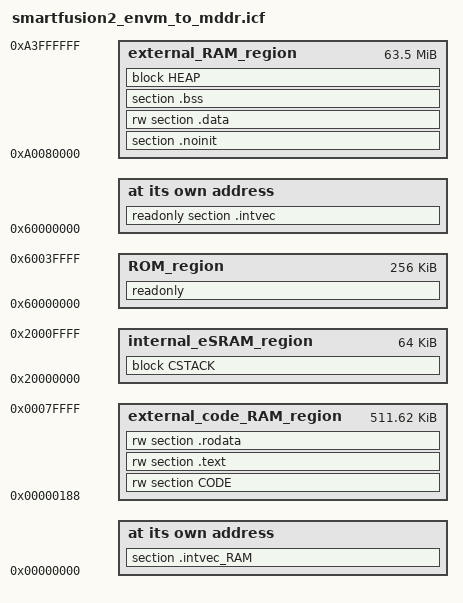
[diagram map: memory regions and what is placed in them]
/******************************************************************************/
/*  (c) Copyright 2015 Microsemi SoC Products Group. All rights reserved.     */
/*  SmartFusion2 linker configuration file for relocating code from eNVM to   */
/*  external RAM.                                                             */
/*                                                                            */
/*  SVN $Revision: 7732 $                                                     */
/*  SVN $Date: 2015-09-02 15:26:06 +0100 (Wed, 02 Sep 2015) $                 */
/*                                                                            */
/*  Please Note!!!!!!                                                         */
/*  The following pre-processor define must be added to the project when      */
/*  using this script- envm to mddr. This is to ensure interrupt vectors and  */ 
/*  associated code is relocated to external memory                           */
/*  MSCC_RELOCATE_CODE_TO_EXT_RAM                                             */ 
/******************************************************************************/
/* 
 * Some current (April 2015) dev kit memory map possibilities are
 * --Type-------Device-----------address start---address end----size---Dbus--RAM IC-------SF2--Comment---------------
 * --eNVM-------M2S010-----------0x60000000------0x6007FFFF-----256KB---------------------010------------------------
 * --eNVM-------M2S090-----------0x60000000------0x6007FFFF-----512KB---------------------090------------------------
 * --eSRAM------M2Sxxx-----------0x20000000------0x2000FFFF-----64KB----------------------xxx--All have same amount--
 * --eSRAM------M2Sxxx-----------0x20000000------0x20013FFF-----80KB----------------------xxx--If ECC/SECDED not used
 * --Fabric-----M2S010-----------0x30000000------0x6007FFFF-----400Kb---------------------010--note-K bits-----------
 * --Fabric-----M2S090-----------0x30000000------0x6007FFFF-----2074Kb--------------------090--note-K bits-----------
 * --LPDDR------STARTER-KIT------0xA0000000------0xA3FFFFFF-----64MB---16--MT46H32M16-----050------------------------
 * --LPDDR------484-STARTER-KIT--0xA0000000------0xA3FFFFFF-----64MB---16--MT46H32M16-----010------------------------
 * --LPDDR------SEC-EVAL-KIT-----0xA0000000------0xA3FFFFFF-----64MB---16--MT46H32M16LF---090--Security eval kit-----
 * --DDR3-------ADevKit----------0xA0000000------0xBFFFFFFF-----1GB----32--MT41K256M8DA---150------------------------
 * --Some older physical memory map possibilities are
 * --Type-------location---------address start---address end----size---Dbus---RAM IC------SF2--Comment--------------
 * --LPDDR------EVAL KIT---------0xA0000000------0xA3FFFFFF-----64MB-=-16--MT46H32M16LF---025--Eval Kit--------------
 * --DDR3-------DevKit-----------0xA0000000------0xAFFFFFFF-----512MB--16--MT41K256M8DA---050------------------------
 */
/*###ICF### Section handled by ICF editor, don't touch! ****/
/*-Editor annotation file-*/
/* IcfEditorFile="$TOOLKIT_DIR$\config\ide\IcfEditor\cortex_v1_0.xml" */
/*-Specials-*/
define symbol __ICFEDIT_intvec_start__ = 0x60000000;
/*-Memory Regions-*/
define symbol __ICFEDIT_region_ROM_start__ = 0x60000000;
define symbol __ICFEDIT_region_ROM_end__   = 0x6003FFFF;
define symbol __ICFEDIT_region_RAM_start__ = 0xA0080000;
define symbol __ICFEDIT_region_RAM_end__   = 0xA3FFFFFF;
/*-Sizes-*/
define symbol __ICFEDIT_size_cstack__ = 0x1000;
define symbol __ICFEDIT_size_heap__   = 0x8000;
/**** End of ICF editor section. ###ICF###*/

define symbol region_internal_eSRAM_start = 0x20000000;
define symbol region_internal_eSRAM_end   = 0x2000FFFF;

define symbol region_external_code_RAM_start = 0x00000188;
define symbol region_external_code_RAM_end = 0x0007FFFF;

define symbol RAM_vectors_start = 0x00000000;

define memory mem with size = 4G;
define region ROM_region   = mem:[from __ICFEDIT_region_ROM_start__   to __ICFEDIT_region_ROM_end__];
define region internal_eSRAM_region   = mem:[from region_internal_eSRAM_start   to region_internal_eSRAM_end];

define region external_RAM_region   = mem:[from __ICFEDIT_region_RAM_start__   to __ICFEDIT_region_RAM_end__];

define region external_code_RAM_region = mem:[from region_external_code_RAM_start   to region_external_code_RAM_end];

define block CSTACK    with alignment = 8, size = __ICFEDIT_size_cstack__   { };
define block HEAP      with alignment = 8, size = __ICFEDIT_size_heap__     { };

/*  Please Note!!!!!!                                                         */
/*  The following pre-processor define must be added to the project when      */
/*  using this script- envm to mddr. This is to ensure interrupt vectors and  */ 
/*  associated code is relocated to external memory                           */
/*  MSCC_RELOCATE_CODE_TO_EXT_RAM                                             */
initialize by copy with packing = none { readonly, readwrite };
do not initialize  { section .noinit };

place at address mem:__ICFEDIT_intvec_start__ { readonly section .intvec };
place at address mem:RAM_vectors_start { section .intvec_RAM };

place in ROM_region   { readonly };
place in external_code_RAM_region { rw section CODE, rw section .text, rw section .rodata };
place in internal_eSRAM_region   { block CSTACK };
place in external_RAM_region   { section .noinit, rw section .data, section .bss, block HEAP };

/* Note taken from IAR system Technical Note 11578 -- Linker protection of start up code        */ 
/* The linker protects sections that are referenced from the startup code from being affected   */ 
/* by an 'initialize by copy' directive.                                                        */ 
/* This includes                                                                                */ 
/*      * __low_level_init and all functions called and/or defined in the same                  */ 
/*       compilation unit (.c file)                                                             */ 
/*      * global (statically linked) C/C++ symbols                                              */ 
/* So the linker ensures that only code that runs after copy initialization has been finished   */ 
/* will be copied to RAM. For this reason it is safe to add readonly in the                     */ 
/* initialize by copy { readonly, readwrite }; command.                                         */ 
/* The linker log (option --log sections) is extended in EWARM 6.10 with information of symbols */ 
/* marked as 'needed for init'.                                                                 */ 
/* Look at the end of the generated log file if you want to see a list of the items not copied  */
/* e.g.:                                                                                        */
/* The following sections would have been initialized by copy but were                          */
/*   excluded because they were marked as possibly 'needed for init':                           */
/*    .intvec (vector_table.o #8)                                                               */
/*    .rodata (sys_config.o #8)                                                                 */
/*    .rodata (sys_config.o #9)                                                                 */
/*    ...                                                                                       */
